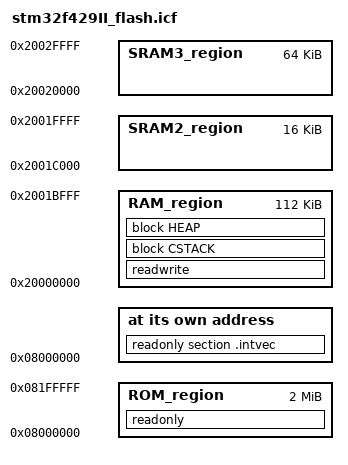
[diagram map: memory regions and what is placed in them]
/*###ICF### Section handled by ICF editor, don't touch! ****/
/*-Editor annotation file-*/
/* IcfEditorFile="$TOOLKIT_DIR$\config\ide\IcfEditor\cortex_v1_0.xml" */
/*-Specials-*/
define symbol __ICFEDIT_intvec_start__ = 0x08000000;
/*-Memory Regions-*/
define symbol __ICFEDIT_region_ROM_start__  = 0x08000000;
define symbol __ICFEDIT_region_ROM_end__    = 0x081FFFFF;
define symbol __ICFEDIT_region_RAM_start__  = 0x20000000;
define symbol __ICFEDIT_region_RAM_end__    = 0x2001BFFF;  // 112 K RAM
/*-Sizes-*/
define symbol __ICFEDIT_size_cstack__ = 0x200;
define symbol __ICFEDIT_size_heap__   = 0x400;
/**** End of ICF editor section. ###ICF###*/

define symbol __ICFEDIT_region_SRAM2_start__ = 0x2001C000;
define symbol __ICFEDIT_region_SRAM2_end__   = 0x2001FFFF;  // 16 K RAM
define symbol __ICFEDIT_region_SRAM3_start__ = 0x20020000;
define symbol __ICFEDIT_region_SRAM3_end__   = 0x2002FFFF;  // 64 K RAM

define memory mem with size = 4G;
define region ROM_region   = mem:[from __ICFEDIT_region_ROM_start__   to __ICFEDIT_region_ROM_end__];
define region RAM_region   = mem:[from __ICFEDIT_region_RAM_start__   to __ICFEDIT_region_RAM_end__];

define region SRAM2_region = mem:[from __ICFEDIT_region_SRAM2_start__ to __ICFEDIT_region_SRAM2_end__];
define region SRAM3_region = mem:[from __ICFEDIT_region_SRAM3_start__ to __ICFEDIT_region_SRAM3_end__];

define block CSTACK    with alignment = 8, size = __ICFEDIT_size_cstack__   { };
define block HEAP      with alignment = 8, size = __ICFEDIT_size_heap__     { };

initialize by copy { readwrite };
do not initialize  { section .noinit };

place at address mem:__ICFEDIT_intvec_start__ { readonly section .intvec };

place in ROM_region   { readonly };
place in RAM_region   { readwrite,
                        block CSTACK, block HEAP };
